# nrf9230_cellcore register map
Vendor: Nordic Semiconductor; Series: nRF92; File version: 1
CPU: CM33 r0p4, little endian, MPU, FPU, 3 interrupt priority bits, 480 interrupts, 8 SAU regions
Registers are 32-bit, read-write, reset 0x0 unless marked. A register's access mark holds for its fields unless they carry their own. Offsets are from the block's base; [hi:lo] are bit positions; lines under a group give offsets from that group; 'fields as' and 'values as' point back to an identical list.

## GLOBAL_TBM_NS — Trace buffer monitor 0
Base 0xBF003000
Same registers: GLOBAL_TBM_S 0xBF003000 (alternate view of GLOBAL_TBM_NS)
0x00 TASKS_START wo — Start counter
  [0] TASKS_START
    1=Trigger task
0x04 TASKS_STOP wo — Stop counter, clear counter value
  [0] TASKS_STOP
    1=Trigger task
0x08 TASKS_FLUSH wo — Save current counter value to COUNTSNAPSHOT
  [0] TASKS_FLUSH
    1=Trigger task
0x100 EVENTS_HALFFULL — Counter value equals half-full
  [0] EVENTS_HALFFULL
    0=NotGenerated (Event not generated); 1=Generated (Event generated)
0x104 EVENTS_FULL — Counter value equals full
  [0] EVENTS_FULL
    values as EVENTS_HALFFULL.EVENTS_HALFFULL
0x108 EVENTS_FLUSH — Counter value saved to COUNTSNAPSHOT due to flush
  [0] EVENTS_FLUSH
    values as EVENTS_HALFFULL.EVENTS_HALFFULL
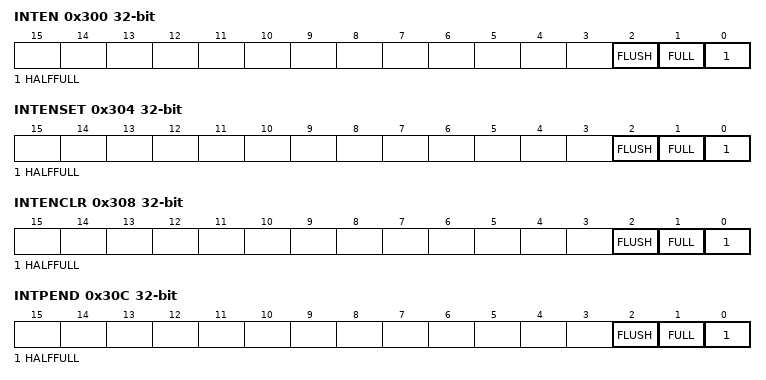
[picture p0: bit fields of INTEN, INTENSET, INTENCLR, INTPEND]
0x300 INTEN — Enable or disable interrupt
  [all] fields
    0=Disabled; 1=Enabled
  [2] FLUSH — Enable or disable interrupt for event FLUSH
  [1] FULL — Enable or disable interrupt for event FULL
  [0] HALFFULL — Enable or disable interrupt for event HALFFULL
0x304 INTENSET — Enable interrupt
  [all] fields
    on read: 0=Disabled (Read: Disabled); 1=Enabled (Read: Enabled) | on write: 1=Set (Enable)
  [2] FLUSH — Write '1' to enable interrupt for event FLUSH
  [1] FULL — Write '1' to enable interrupt for event FULL
  [0] HALFFULL — Write '1' to enable interrupt for event HALFFULL
0x308 INTENCLR — Disable interrupt
  [all] fields
    on read: 0=Disabled (Read: Disabled); 1=Enabled (Read: Enabled) | on write: 1=Clear (Disable)
  [2] FLUSH — Write '1' to disable interrupt for event FLUSH
  [1] FULL — Write '1' to disable interrupt for event FULL
  [0] HALFFULL — Write '1' to disable interrupt for event HALFFULL
0x30C INTPEND ro — Pending interrupts
  [all] fields
    on read: 0=NotPending (Read: Not pending); 1=Pending (Read: Pending)
  [2] FLUSH — Read pending status of interrupt for event FLUSH
  [1] FULL — Read pending status of interrupt for event FULL
  [0] HALFFULL — Read pending status of interrupt for event HALFFULL
0x400 BUFFERSIZE reset 0x400 — System RAM trace buffer total size in bytes
  [12:0] BUFFERSIZE — Must only be configured in STOP mode. Must be programmed to multiple of 16 bytes to make half-buffer size always 64 bit word aligned. Typical minimum BUFFERSIZE value 0x010 i.e. 16 bytes, typical maximum value 0x1000 i.e. 4096 bytes.
    0=Zero (0 bytes); 16=Min (16 bytes); 0x1000=Max (4096 bytes)
0x404 COUNT — Counter current value
  [12:0] COUNT — Counter current value. Only writable when counter is in stopped state. Writing when not in stopped state will generate a bus fault.
0x408 COUNTSNAPSHOT ro — Copy of the current COUNT value
  [12:0] COUNTSNAPSHOT — TASKS_FLUSH will copy the current COUNT value to this register.

## GLOBAL_CANPLLPM_S — AUXPM 0
Base 0x5F8C2000
Same registers: GLOBAL_AUDIOPLLPM_NS 0x5F968000, GLOBAL_AUDIOPLLPM_S 0x5F968000 (alternate view of GLOBAL_AUDIOPLLPM_NS)
0x20 TASKS_START wo — Request power up
  [0] TASKS_START
    1=Trigger task
0x24 TASKS_STOP wo — Stop requesting power up
  [0] TASKS_STOP
    1=Trigger task
0x110 EVENTS_SETTLED — LDO settled
  [0] EVENTS_SETTLED
    0=NotGenerated (Event not generated); 1=Generated (Event generated)
0x300 INTEN — Enable or disable interrupt
  [4] SETTLED — Enable or disable interrupt for event SETTLED
    0=Disabled; 1=Enabled
0x304 INTENSET — Enable interrupt
  [4] SETTLED — Write '1' to enable interrupt for event SETTLED
    on read: 0=Disabled (Read: Disabled); 1=Enabled (Read: Enabled) | on write: 1=Set (Enable)
0x308 INTENCLR — Disable interrupt
  [4] SETTLED — Write '1' to disable interrupt for event SETTLED
    on read: 0=Disabled (Read: Disabled); 1=Enabled (Read: Enabled) | on write: 1=Clear (Disable)
0x30C INTPEND ro — Pending interrupts
  [4] SETTLED — Read pending status of interrupt for event SETTLED
    on read: 0=NotPending (Read: Not pending); 1=Pending (Read: Pending)
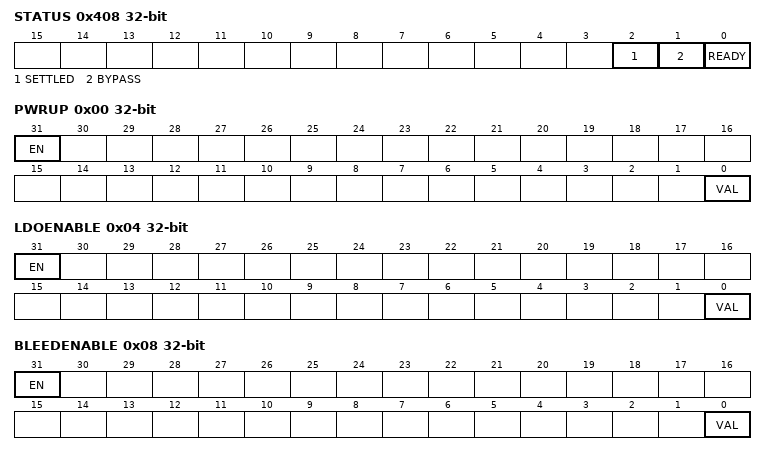
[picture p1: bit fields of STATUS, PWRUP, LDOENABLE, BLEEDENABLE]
0x408 STATUS ro — Status of AuxPm
  [2] SETTLED — LDO settled
    0=NotSettled (AuxPm not settled); 1=Settled (AuxPm settled)
  [1] BYPASS — Bypassing vref filter for startup boost
    0=NotBypass (VrefFilt not bypassed); 1=Bypass (VrefFilt bypassed)
  [0] READY — AuxPm powered up
    0=PowerDown (AuxPm powered down); 1=Powered (AuxPm powered up)
0x420 CONFIG group — Unspecified
  0x00 STARTUPTIME reset 0x18 — Time from pwrup to ready signal (0us-3us)
    [5:0] VAL — Timer value
      0=Min (0 us); 24=Default (1.5 us); 48=Max (3 us)
  0x04 SHUTDOWNTIME reset 0x18 — Time from shutdown until to ready signal is deasserted (0us-3us)
    fields as CONFIG.STARTUPTIME
  0x08 BYPASSTIME reset 0x70 — Time from ready until bypass vref turned off (7us-40us)
    [9:0] VAL — Timer value
      112=Min (7 us); 112=Default (7 us); 0x280=Max (40 us)
  0x0C SETLTIME reset 0x18 — Time from bypass turned off to settled (0us-3us)
    fields as CONFIG.STARTUPTIME
0x450 TRIM group — Unspecified
  0x00 VREFPM — Reference voltage trimming. Equals output voltage
    [2:0] VAL — Voltage trimming value.
      0=Val800mV (800 mV); 1=Val825mV (825 mV); 2=Val850mV (850 mV); 3=Val900mV (900 mV); 4=Val600mV (600 mV); 5=Val650mV (650 mV); 6=Val700mV (700 mV); 7=Val750mV (750 mV)
0x4F0 MIRROR — Enable LOCK for mirrored registers
  [0] LOCK — Lock for mirrored registers
    0=Disabled (Lock disabled); 1=Enabled (Lock enabled)
0x580 OVERRIDE group — Unspecified
  0x00 PWRUP — Override the pwrup to the analog module
    [31] EN — Enable the override
      0=Disabled (Override is disabled); 1=Enabled (Override is enabled)
    [0] VAL — Override value for the signal
  0x04 LDOENABLE — Override the LDO enable to the analog module
    fields as OVERRIDE.PWRUP
  0x08 BLEEDENABLE — Override the bleed enable to the analog module
    fields as OVERRIDE.PWRUP
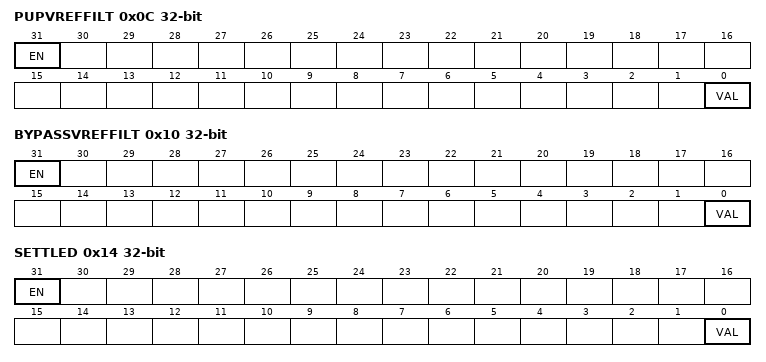
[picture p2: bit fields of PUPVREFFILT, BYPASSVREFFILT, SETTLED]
  0x0C PUPVREFFILT — Override the vref filter enable to the analog module
    fields as OVERRIDE.PWRUP
  0x10 BYPASSVREFFILT — Override the vref bypass to the analog module
    fields as OVERRIDE.PWRUP
  0x14 SETTLED — Override the SETTLED from the digital part
    fields as OVERRIDE.PWRUP
0x680 DFT group — Unspecified
  0x00 ATB0CONFIG — Analog Test Bus 0 (ATB0) configuration
    [31] EN
      0=Disabled (Analog test bus is disabled); 1=Enabled (Analog test bus is enabled)
  0x04 ATB1CONFIG — Analog Test Bus 1 (ATB1) configuration
    fields as DFT.ATB0CONFIG
